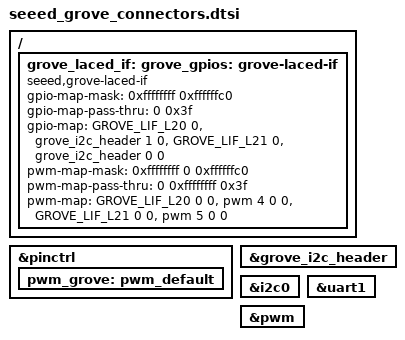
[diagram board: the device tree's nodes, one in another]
/*
 * SPDX-FileCopyrightText: Copyright (c) 2023-2026 TiaC Systems
 * SPDX-License-Identifier: Apache-2.0
 */

#include <bridle/dt-bindings/seeed_grove_pwms_defaults.h>

&pinctrl {
	pwm_grove: pwm_default {};
};

#include "seeed_grove_i2c_connector.dtsi"

grove_uart_header: &grove_i2c_header {};	/* UART1-RX/TX is on I2C0-SCL/SDA */
grove_d20_header: &grove_i2c_header {};		/* D20 is on I2C header pin 2 */
grove_d21_header: &grove_d20_header {};		/* D21 is on D20 header pin 1 */

#include <zephyr/dt-bindings/gpio/grove-laced-if.h>

/ {
	grove_laced_if: grove-laced-if {
		compatible = "seeed,grove-laced-if";

		#gpio-cells = <2>;
		gpio-map-mask = <0xffffffff 0xffffffc0>;
		gpio-map-pass-thru = <0 0x3f>;
		gpio-map =
			/*  0 - GP0:  not wired */
			/*  1 - GP1:  not wired */
			/*  2 - GP2:  not wired */
			/*  3 - GP3:  not wired */
			/*  4 - GP4:  not wired */
			/*  5 - GP5:  not wired */
			/*  6 - GP6:  not wired */
			/*  7 - GP7:  not wired */
			/*  8 - GP8:  not wired */
			/*  9 - GP9:  not wired */
			/* 10 - GP10: not wired */
			/* 11 - GP11: not wired */
			/* 12 - GP12: not wired */
			/* 13 - GP13: not wired */
			/* 14 - GP14: not wired */
			/* 15 - GP15: not wired */
			/* 16 - GP16: not wired */
			/* 17 - GP17: not wired */
			/* 18 - GP18: not wired */
			/* 19 - GP19: not wired */
			<GROVE_LIF_L20 0 &grove_i2c_header 1 0>,/* GP20: I2C0-SDA as GPIO */
			<GROVE_LIF_L21 0 &grove_i2c_header 0 0>;/* GP21: I2C0-SCL as GPIO */
			/* 22 - GP22: not wired */
			/* 23 - GP23: not wired */
			/* 24 - GP24: not wired */
			/* 25 - GP25: not wired */
			/* 26 - GP26: not wired */
			/* 27 - GP27: not wired */
			/* 28 - GP28: not wired */
			/* 29 - GP29: not wired */

		#pwm-cells = <3>;
		pwm-map-mask = <0xffffffff 0 0xffffffc0>;
		pwm-map-pass-thru = <0 0xffffffff 0x3f>;
		pwm-map =
			/*  0 - GP0:  PWM0CHA (0)  not wired */
			/*  1 - GP1:  PWM0CHB (1)  not wired */
			/*  2 - GP2:  PWM1CHA (2)  not wired */
			/*  3 - GP3:  PWM1CHB (3)  not wired */
			/*  4 - GP4:  PWM2CHA (4)  not wired */
			/*  5 - GP5:  PWM2CHB (5)  not wired */
			/*  6 - GP6:  PWM3CHA (6)  not wired */
			/*  7 - GP7:  PWM3CHB (7)  not wired */
			/*  8 - GP8:  PWM4CHA (8)  not wired */
			/*  9 - GP9:  PWM4CHB (9)  not wired */
			/* 10 - GP10: PWM5CHA (10) not wired */
			/* 11 - GP11: PWM5CHB (11) not wired */
			/* 12 - GP12: PWM6CHA (12) not wired */
			/* 13 - GP13: PWM6CHB (13) not wired */
			/* 14 - GP14: PWM7CHA (14) not wired */
			/* 15 - GP15: PWM7CHB (15) not wired */
			/* 16 - GP16: PWM0CHA (0)  not wired */
			/* 17 - GP17: PWM0CHB (1)  not wired */
			/* 18 - GP18: PWM1CHA (2)  not wired */
			/* 19 - GP19: PWM1CHB (3)  not wired */
			<GROVE_LIF_L20 0 0 &pwm 4 0 0>,		/* GP20: PWM2CHA (4) */
			<GROVE_LIF_L21 0 0 &pwm 5 0 0>;		/* GP21: PWM2CHB (5) */
			/* 22 - GP22: PWM3CHA (6)  not wired */
			/* 23 - GP23: PWM3CHB (7)  not wired */
			/* 24 - GP24: PWM4CHA (8)  not wired */
			/* 25 - GP25: PWM4CHB (9)  not wired */
			/* 26 - GP26: A0 as PWM5CHA (10) not wired */
			/* 27 - GP27: A1 as PWM5CHB (11) not wired */
			/* 28 - GP28: A2 as PWM6CHA (12) not wired */
			/* 29 - GP29: A3 as PWM6CHB (13) not wired */
	};
};

zephyr_i2c: &i2c0 {};

grove_i2c: &zephyr_i2c {};
grove_serial: &uart1 {};
grove_gpios: &grove_laced_if {};
grove_pwms: &grove_laced_if {};

grove_pwm_d20: &pwm {};
grove_pwm_d21: &pwm {};
